# PIC32CX5112MTSH128S1 register map
Vendor: Microchip Technology; Series: PIC32CXMTSH; File version: 0
CPU: CM4 r0p1, little endian, MPU, FPU, 4 interrupt priority bits, 96 interrupts
Registers are 32-bit, read-write, reset 0x0 unless marked. A register's access mark holds for its fields unless they carry their own. Offsets are from the block's base; [hi:lo] are bit positions; 'fields as' and 'values as' point back to an identical list.

## SFR — Special Function Register
Base 0x40050400
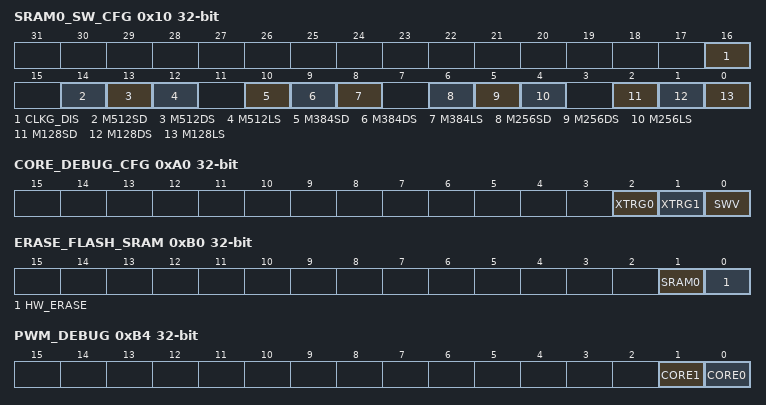
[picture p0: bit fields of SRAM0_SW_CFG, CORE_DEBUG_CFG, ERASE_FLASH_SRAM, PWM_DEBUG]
0x10 SRAM0_SW_CFG — SRAM0 Software Config Register
  [16] CLKG_DIS — Clock Gating Disable
  [14] M512SD — 512 KB Shutdown Mode
  [13] M512DS — 512 KB Deep Sleep Mode
  [12] M512LS — 512 KB Light Sleep Mode
  [10] M384SD — 384 KB Shutdown Mode
  [9] M384DS — 384 KB Deep Sleep Mode
  [8] M384LS — 384 KB Light Sleep Mode
  [6] M256SD — 256 KB Shutdown Mode
  [5] M256DS — 256 KB Deep Sleep Mode
  [4] M256LS — 256 KB Light Sleep Mode
  [2] M128SD — 128 KB Shutdown Mode
  [1] M128DS — 128 KB Deep Sleep Mode
  [0] M128LS — 128 KB Light Sleep Mode
0x70 FLASH — Flash Memory Configuration Register
  [0] PATCH_BYPASS
0x80 OPT_LINK — Optical Link Register
  [0] CLK_SELECT — Clock Selection
0xA0 CORE_DEBUG_CFG — Core Debug Configuration Register
  [2] XTRG0 — From Core 0 to Core 1 Cross Triggering
  [1] XTRG1 — From Core 1 to Core 0 Cross Triggering
  [0] SWV — SWV Selection
0xB0 ERASE_FLASH_SRAM
  [1] SRAM0 — Erase SRAM0 Content
    0=NOT_DELETED (If HW_ERASE = 1, and HW erase signal assertion occurs, SRAM0 content is not deleted.); 1=DELETED (If HW_ERASE = 1, and HW erase signal assertion occurs, SRAM0 content is deleted.)
  [0] HW_ERASE — PB2/Peripherals or Hardware Erase Signal Assignment
    0=DISABLE (Hardware erase signal disabled. PB2 pin can be used in GPIO or Peripheral IO mode.); 1=ENABLE (Hardware erase signal enabled. PB2 pin is assigned to Flash erase function.)
0xB4 PWM_DEBUG
  [1] CORE1 — Debug Information Propagation Mode
    0=NOT_SENT (Core x does not send the debug signal to the PWM.); 1=SENT (Core x sends the debug signal to PWM. Refer to 'Debug Mode' in the section 'Pulse Width Modulation Controller (PWM)' for details on configuring an action when the debug signal is active.)
  [0] CORE0 — Debug Information Propagation Mode
    values as CORE1
0xBC WAIT_MODE — Improved Wait Mode Register
  [0] CONTROL — Improved Wait Mode Control
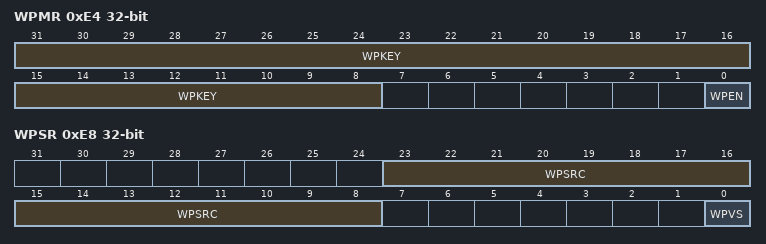
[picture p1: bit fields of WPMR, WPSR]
0xE4 WPMR — Write Protection Mode Register
  [31:8] WPKEY — Write Protection Key
    0x534652=PASSWD (Writing any other value in this field aborts the write operation of the WPEN bit. Always reads as 0.)
  [0] WPEN — Write Protection Enable
0xE8 WPSR — Write Protection Status Register
  [23:8] WPSRC — Write Protection Source
  [0] WPVS — Write Protection Violation Status

## SFRBU — Special Function Register Backup
Base 0x40050600
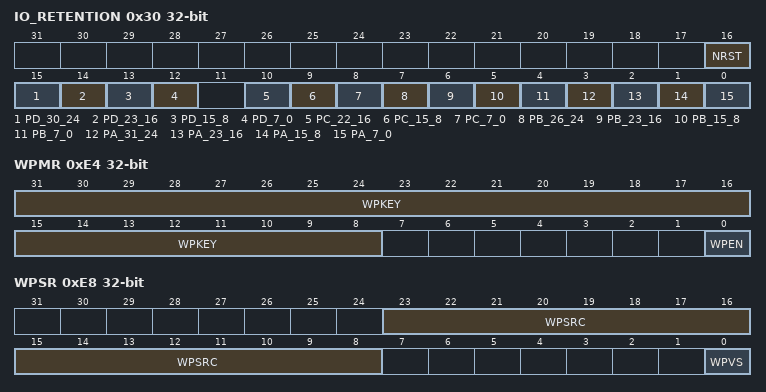
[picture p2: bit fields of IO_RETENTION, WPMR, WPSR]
0x30 IO_RETENTION
  [16] NRST — Keep Function on NRST
  [15] PD_30_24 — Keep Function on PD24 to PD30
  [14] PD_23_16 — Keep Function on PD16 to PD23
  [13] PD_15_8 — Keep Function on PD8 to PD15
  [12] PD_7_0 — Keep Function on PD0 to PD7
  [10] PC_22_16 — Keep Function on PC16 to PC22
  [9] PC_15_8 — Keep Function on PC8 to PC15
  [8] PC_7_0 — Keep Function on PC0 to PC7
  [7] PB_26_24 — Keep Function on PB24 to PB26
  [6] PB_23_16 — Keep Function on PB216 to PB23
  [5] PB_15_8 — Keep Function on PB8 to PB15
  [4] PB_7_0 — Keep Function on PB0 to PB7
  [3] PA_31_24 — Keep Function on PA24 to PA31
  [2] PA_23_16 — Keep Function on PA16 to PA23
  [1] PA_15_8 — Keep Function on PA8 to PA15
  [0] PA_7_0 — Keep Function on PA0 to PA7
0x40 BODCORE
  [0] STATUS — Core Brownout Detector
0xE4 WPMR — Write Protection Mode Register
  [31:8] WPKEY — Write Protection Key
    0x534652=PASSWD (Writing any other value in this field aborts the write operation of the WPEN bit. Always reads as 0.)
  [0] WPEN — Write Protection Enable
0xE8 WPSR — Write Protection Status Register
  [23:8] WPSRC — Write Protection Source
  [0] WPVS — Write Protection Violation Status

## SYSCWP — External Interrupt Controller
Base 0x400531A0
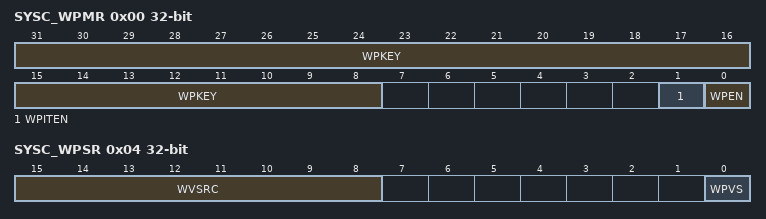
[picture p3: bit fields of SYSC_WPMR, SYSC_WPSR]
0x00 SYSC_WPMR — Write Protection Mode Register
  [31:8] WPKEY — Write Protection Key
    0x535943=PASSWD (Writing any other value in this field aborts the write operation of the WPEN and WPITEN bits. Always reads as 0.)
  [1] WPITEN — Write Protection Interrupt Enable
  [0] WPEN — Write Protection Enable
0x04 SYSC_WPSR ro — Write Protection Status Register
  [15:8] WVSRC — Write Violation Source
  [0] WPVS — Write Protection Register Violation Status

## Notices in the file
Copyright (c) 2025 Microchip Technology Inc.
SPDX-License-Identifier: Apache-2.0
Licensed under the Apache License, Version 2.0 (the "License");
you may not use this file except in compliance with the License.
You may obtain a copy of the License at
http://www.apache.org/licenses/LICENSE-2.0
Unless required by applicable law or agreed to in writing, software
distributed under the License is distributed on an "AS IS" BASIS,
WITHOUT WARRANTIES OR CONDITIONS OF ANY KIND, either express or implied.
See the License for the specific language governing permissions and
limitations under the License.
